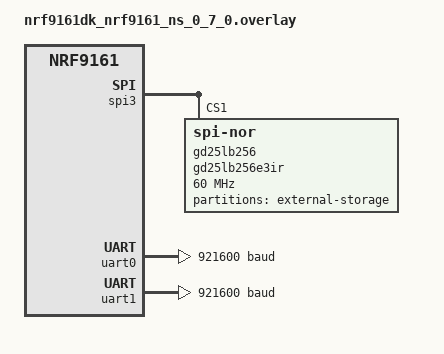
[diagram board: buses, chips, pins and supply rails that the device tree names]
/*  This overlay file supports v0.97X of the nrf9161dk board
 *  V0.7.X uses the gd25lb256 SPI FLASH
 *  instead of the gd25wb256 used on v0.9.X
 *
 *  Notes:
 *  1. 9161DK v0.7.X uses gd25lb256 with jedec-id = [c8 67 19]
 *  2. It should be possible to remove the &spi3 below
 *     when Zephyr is upgraded to v.3.x (nrf SDK v2.5.x).
 */

/* Add for 9161DK v0.7.x */
&spi3 {
	gd25lb256: gd25lb256e3ir@1 {
		compatible = "jedec,spi-nor";
		status = "disabled";
		reg = <1>;
		spi-max-frequency = <60000000>;
		jedec-id = [c8 67 19];
		sfdp-bfp = [
			e5 20 ea ff  ff ff ff 0f  44 eb 08 6b  00 3b 00 bb
			fe ff ff ff  ff ff 00 ff  ff ff 44 eb  0c 20 0f 52
			10 d8 00 ff  d5 31 b1 fe  82 e4 14 4c  ec 60 06 33
			7a 75 7a 75  04 bd d5 5c  29 06 74 00  08 50 00 01
		];
		size = <268435456>;
		has-dpd;
		t-enter-dpd = <3000>;
		t-exit-dpd = <30000>;
	};
};

/* Explicitly disable serial FLASH from nrf9161dk_nrf9161.overlay file */
&gd25wb256 {
	status = "disabled";
};

&gd25lb256 {
	status = "okay";
	partitions {
		compatible = "fixed-partitions";
		#address-cells = <1>;
		#size-cells = <1>;

		external_flash_storage: partition@0 {
			label = "external-storage";
			reg = <0x00000000 0x1e84800>;
		};
	};
};

/* Add uart aliases for v2.2.0 of nRF SDK  */
/ {
	aliases {
		uart0 = &uart0;
		uart1 = &uart1;
	};
	chosen {
		nordic,pm-ext-flash = &gd25lb256;
	};
};

&uart0 {
	status = "okay";
	current-speed = <921600>;
};

&uart1 {
	status = "okay";
	current-speed = <921600>;
	hw-flow-control;
};
